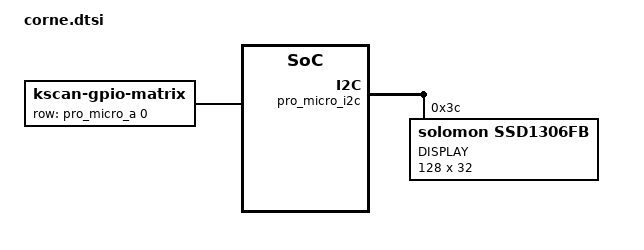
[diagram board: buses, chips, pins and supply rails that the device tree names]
/*
 * Copyright (c) 2020 Pete Johanson
 *
 * SPDX-License-Identifier: MIT
 */

#include <dt-bindings/zmk/matrix_transform.h>

/ {
	chosen {
		zmk,kscan = &kscan0;
		zmk,matrix_transform = &default_transform;
	};

	default_transform: keymap_transform_0 {
		compatible = "zmk,matrix-transform";
		columns = <4>;
		rows = <1>;
		map = <
RC(0,0) RC(0,1) RC(0,2) RC(0,3)
		>;
	};

	kscan0: kscan {
		compatible = "zmk,kscan-gpio-matrix";
		label = "KSCAN";

		diode-direction = "col2row";
		row-gpios
			= <&pro_micro_a 0 (GPIO_ACTIVE_HIGH | GPIO_PULL_DOWN)>
			;
		
	};

	// TODO: per-key RGB node(s)?
};

&pro_micro_i2c {
	status = "okay";

	oled: ssd1306@3c {
		compatible = "solomon,ssd1306fb";
		reg = <0x3c>;
		label = "DISPLAY";
		width = <128>;
		height = <32>;
		segment-offset = <0>;
		page-offset = <0>;
		display-offset = <0>;
		multiplex-ratio = <31>;
		segment-remap;
		com-invdir;
		com-sequential;
		prechargep = <0x22>;
	};
};
